AUTOSAR XML (schema 4-3-0)
standard types defined: boolean, uint8, boolean_CompuMethod, boolean_DataConstr, uint8_DataConstr
package /ComponentTypes/HkmcDiagSWC
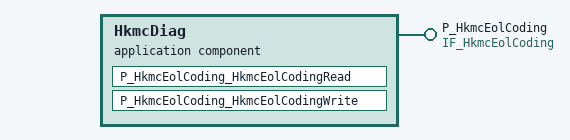
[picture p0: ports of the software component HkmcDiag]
  application sw component type HkmcDiag
    provide port P_HkmcEolCoding: provided-com-specs=[{operation=HkmcEolCodingRead, queue-length=1}, {operation=HkmcEolCodingWrite, queue-length=1}], provided-interface=IF_HkmcEolCoding
    behavior HkmcDiag_InternalBehavior
      operation invoked event OIT_P_HkmcEolCoding_HkmcEolCodingRead_P_HkmcEolCoding_HkmcEolCodingRead: start-on-event=P_HkmcEolCoding_HkmcEolCodingRead, operation=P_HkmcEolCoding.HkmcEolCodingRead
      operation invoked event OIT_P_HkmcEolCoding_HkmcEolCodingWrite_P_HkmcEolCoding_HkmcEolCodingWrite: start-on-event=P_HkmcEolCoding_HkmcEolCodingWrite, operation=P_HkmcEolCoding.HkmcEolCodingWrite
      runnable P_HkmcEolCoding_HkmcEolCodingRead
      runnable P_HkmcEolCoding_HkmcEolCodingWrite
  swc implementation HkmcDiag_Implementation: behavior=HkmcDiag_InternalBehavior
    code-descriptors:
      code Default: artifact-descriptors=autosar-engineering-object={short-label=Default, category=SWSRC}
package /ComponentTypes/HkmcDiagSWC/DataTypes
  impl type HkmcEolData: category=STRUCTURE, type-emitter=RTE
    8 x element, all with category=TYPE_REFERENCE, implementation-data-type=uint8:
      data{1..8}
package /ComponentTypes/HkmcDiagSWC/PortInterfaces
  client server interface IF_HkmcEolCoding: is-service=true
    operation HkmcEolCodingRead
      arg EolDataIn: type=HkmcEolData, direction=IN, server-argument-impl-policy=USE-ARGUMENT-TYPE
      arg ReadStatus: type=boolean, direction=OUT, server-argument-impl-policy=USE-ARGUMENT-TYPE
    operation HkmcEolCodingWrite
      arg EolDataIn: type=HkmcEolData, direction=IN, server-argument-impl-policy=USE-ARGUMENT-TYPE
      arg WriteStatus: type=boolean, direction=OUT, server-argument-impl-policy=USE-ARGUMENT-TYPE
